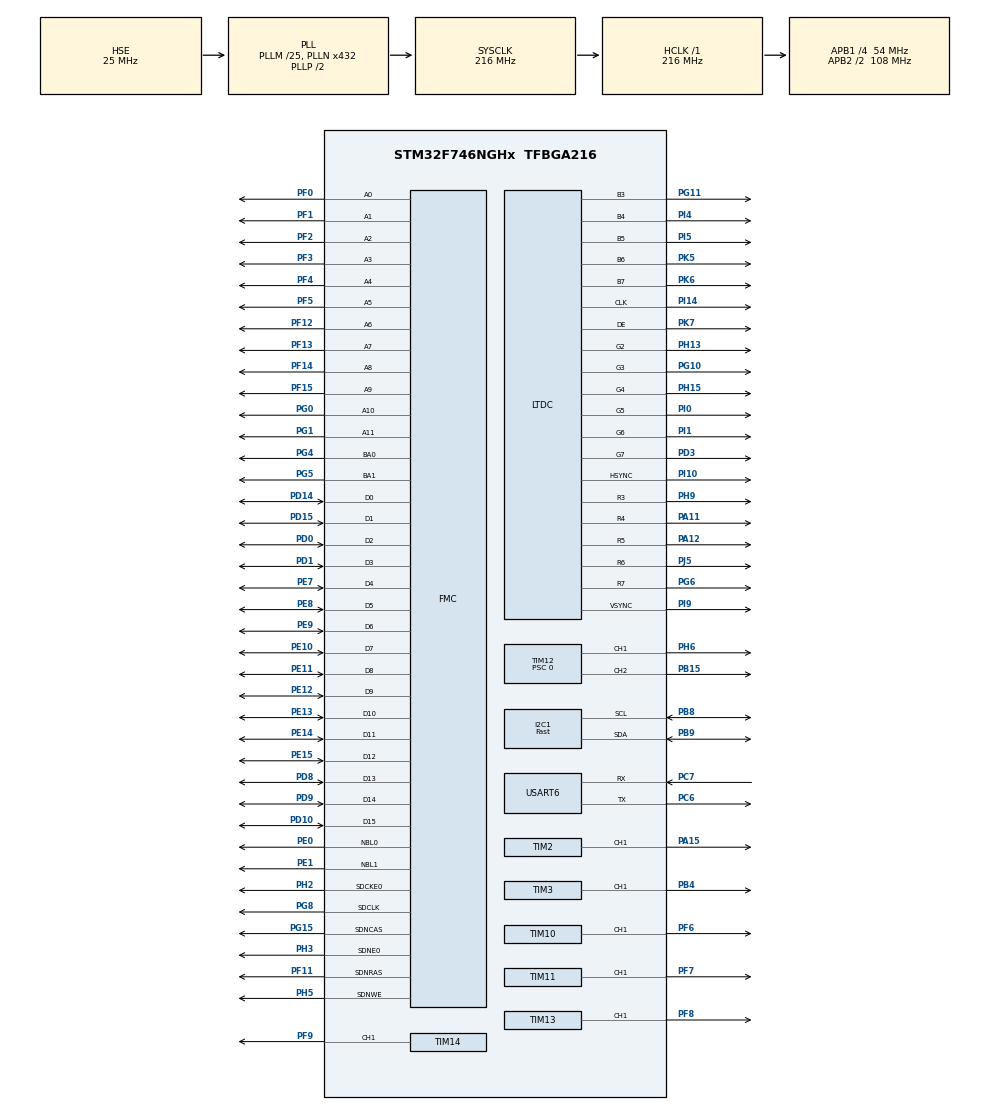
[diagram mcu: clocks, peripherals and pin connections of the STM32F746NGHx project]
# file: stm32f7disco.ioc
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CORTEX_M7.default_mode_Activation=1
DMA2D.ColorMode=DMA2D_OUTPUT_RGB565
FMC.CASLatency1=FMC_SDRAM_CAS_LATENCY_3
FMC.ExitSelfRefreshDelay1=7
FMC.LoadToActiveDelay1=2
FMC.RPDelay1=2
FMC.RPDelay2=2
FMC.ReadBurst1=FMC_SDRAM_RBURST_ENABLE
FMC.ReadBurst2=FMC_SDRAM_RBURST_ENABLE
FMC.RowCycleDelay1=7
FMC.RowCycleDelay2=7
FMC.SDClockPeriod1=FMC_SDRAM_CLOCK_PERIOD_2
FMC.SDClockPeriod2=FMC_SDRAM_CLOCK_PERIOD_2
FMC.SelfRefreshTime1=4
FMC.WriteRecoveryTime1=3
I2C1.I2C_Speed_Mode=I2C_Fast
I2C1.Timing=0x6000030D
LTDC.ActiveH=272
LTDC.ActiveW=480
LTDC.Alpha0_L0=255
LTDC.Alpha0_L1=255
LTDC.Alpha_L1=255
LTDC.FBStartAdress_L0=0xC0000000
LTDC.FBStartAdress_L1=0xC0000000
LTDC.HBP=13
LTDC.HFP=32
LTDC.HSync=41
LTDC.ImageHeight_L0=272
LTDC.ImageHeight_L1=272
LTDC.ImageWidth_L0=963
LTDC.ImageWidth_L1=963
LTDC.Layers=0
LTDC.PixelFormat_L0=LTDC_PIXEL_FORMAT_RGB565
LTDC.VSync=10
LTDC.WindowX0_L1=0
LTDC.WindowX1_L0=480
LTDC.WindowX1_L1=480
LTDC.WindowY1_L0=272
LTDC.WindowY1_L1=272
Mcu.Family=STM32F7
Mcu.Name=STM32F746NGHx
Mcu.Package=TFBGA216
NVIC.PriorityGroup=NVIC_PRIORITYGROUP_4
PA11.Mode=RGB565
PA11.Signal=LTDC_R4
PA12.Mode=RGB565
PA12.Signal=LTDC_R5
PA15.Signal=S_TIM2_CH1_ETR
PB15.Signal=S_TIM12_CH2
PB4.Signal=S_TIM3_CH1
PB8.Mode=I2C
PB8.Signal=I2C1_SCL
PB9.Mode=I2C
PB9.Signal=I2C1_SDA
PC6.Mode=Asynchronous
PC6.Signal=USART6_TX
PC7.Mode=Asynchronous
PC7.Signal=USART6_RX
PD0.Signal=FMC_D2_DA2
PD1.Signal=FMC_D3_DA3
PD10.Signal=FMC_D15_DA15
PD14.Signal=FMC_D0_DA0
PD15.Signal=FMC_D1_DA1
PD3.Mode=RGB565
PD3.Signal=LTDC_G7
PD8.Signal=FMC_D13_DA13
PD9.Signal=FMC_D14_DA14
PE0.Signal=FMC_NBL0
PE1.Signal=FMC_NBL1
PE10.Signal=FMC_D7_DA7
PE11.Signal=FMC_D8_DA8
PE12.Signal=FMC_D9_DA9
PE13.Signal=FMC_D10_DA10
PE14.Signal=FMC_D11_DA11
PE15.Signal=FMC_D12_DA12
PE7.Signal=FMC_D4_DA4
PE8.Signal=FMC_D5_DA5
PE9.Signal=FMC_D6_DA6
PF0.Signal=FMC_A0
PF1.Signal=FMC_A1
PF11.Signal=FMC_SDNRAS
PF12.Signal=FMC_A6
PF13.Signal=FMC_A7
PF14.Signal=FMC_A8
PF15.Signal=FMC_A9
PF2.Signal=FMC_A2
PF3.Signal=FMC_A3
PF4.Signal=FMC_A4
PF5.Signal=FMC_A5
PF6.Signal=S_TIM10_CH1
PF7.Signal=S_TIM11_CH1
PF8.Signal=S_TIM13_CH1
PF9.Signal=S_TIM14_CH1
PG0.Signal=FMC_A10
PG1.Signal=FMC_A11
PG10.Mode=RGB565
PG10.Signal=LTDC_G3
PG11.Mode=RGB565
PG11.Signal=LTDC_B3
PG15.Signal=FMC_SDNCAS
PG4.Signal=FMC_A14_BA0
PG5.Signal=FMC_A15_BA1
PG6.Mode=RGB565
PG6.Signal=LTDC_R7
PG8.Signal=FMC_SDCLK
PH0/OSC_IN.Mode=HSE-External-Clock-Source
PH0/OSC_IN.Signal=RCC_OSC_IN
PH1/OSC_OUT.Mode=HSE-External-Clock-Source
PH1/OSC_OUT.Signal=RCC_OSC_OUT
PH13.Mode=RGB565
PH13.Signal=LTDC_G2
PH15.Mode=RGB565
PH15.Signal=LTDC_G4
PH2.Mode=SdramChipSelect1_1
PH2.Signal=FMC_SDCKE0
PH3.Mode=SdramChipSelect1_1
PH3.Signal=FMC_SDNE0
PH5.Signal=FMC_SDNWE
PH6.Signal=S_TIM12_CH1
PH9.Mode=RGB565
PH9.Signal=LTDC_R3
PI0.Mode=RGB565
PI0.Signal=LTDC_G5
PI1.Mode=RGB565
PI1.Signal=LTDC_G6
PI10.Mode=RGB565
PI10.Signal=LTDC_HSYNC
PI14.Mode=RGB565
PI14.Signal=LTDC_CLK
PI4.Mode=RGB565
PI4.Signal=LTDC_B4
PI5.Mode=RGB565
PI5.Signal=LTDC_B5
PI9.Mode=RGB565
PI9.Signal=LTDC_VSYNC
PJ5.Mode=RGB565
PJ5.Signal=LTDC_R6
PK5.Mode=RGB565
PK5.Signal=LTDC_B6
PK6.Mode=RGB565
PK6.Signal=LTDC_B7
PK7.Mode=RGB565
PK7.Signal=LTDC_DE
ProjectManager.HeapSize=0x200
ProjectManager.StackSize=0x400
ProjectManager.TargetToolchain=STM32CubeIDE
RCC.AHBFreq_Value=216000000
RCC.APB1CLKDivider=RCC_HCLK_DIV4
RCC.APB1Freq_Value=54000000
RCC.APB1TimFreq_Value=108000000
RCC.APB2CLKDivider=RCC_HCLK_DIV2
RCC.APB2Freq_Value=108000000
RCC.APB2TimFreq_Value=216000000
RCC.CortexFreq_Value=216000000
RCC.HCLKFreq_Value=216000000
RCC.HSE_VALUE=25000000
RCC.HSI_VALUE=16000000
RCC.LSE_VALUE=32768
RCC.PLLM=25
RCC.PLLN=432
RCC.PLLSAIR=4
RCC.PLLSourceVirtual=RCC_PLLSOURCE_HSE
RCC.PWR_Regulator_Voltage_Scale=PWR_REGULATOR_VOLTAGE_SCALE1
RCC.SYSCLKFreq_VALUE=216000000
RCC.SYSCLKSource=RCC_SYSCLKSOURCE_PLLCLK
RCC.USBFreq_Value=216000000
RCC.VCOOutputFreq_Value=432000000
SH.FMC_A0.0=FMC_A0,12b-sda1
SH.FMC_A1.0=FMC_A1,12b-sda1
SH.FMC_A10.0=FMC_A10,12b-sda1
SH.FMC_A11.0=FMC_A11,12b-sda1
SH.FMC_A14_BA0.0=FMC_BA0,FourSdramBanks1
SH.FMC_A15_BA1.0=FMC_BA1,FourSdramBanks1
SH.FMC_A2.0=FMC_A2,12b-sda1
SH.FMC_A3.0=FMC_A3,12b-sda1
SH.FMC_A4.0=FMC_A4,12b-sda1
SH.FMC_A5.0=FMC_A5,12b-sda1
SH.FMC_A6.0=FMC_A6,12b-sda1
SH.FMC_A7.0=FMC_A7,12b-sda1
SH.FMC_A8.0=FMC_A8,12b-sda1
SH.FMC_A9.0=FMC_A9,12b-sda1
SH.FMC_D0_DA0.0=FMC_D0,sd-16b-d1
SH.FMC_D10_DA10.0=FMC_D10,sd-16b-d1
SH.FMC_D11_DA11.0=FMC_D11,sd-16b-d1
SH.FMC_D12_DA12.0=FMC_D12,sd-16b-d1
SH.FMC_D13_DA13.0=FMC_D13,sd-16b-d1
SH.FMC_D14_DA14.0=FMC_D14,sd-16b-d1
SH.FMC_D15_DA15.0=FMC_D15,sd-16b-d1
SH.FMC_D1_DA1.0=FMC_D1,sd-16b-d1
SH.FMC_D2_DA2.0=FMC_D2,sd-16b-d1
SH.FMC_D3_DA3.0=FMC_D3,sd-16b-d1
SH.FMC_D4_DA4.0=FMC_D4,sd-16b-d1
SH.FMC_D5_DA5.0=FMC_D5,sd-16b-d1
SH.FMC_D6_DA6.0=FMC_D6,sd-16b-d1
SH.FMC_D7_DA7.0=FMC_D7,sd-16b-d1
SH.FMC_D8_DA8.0=FMC_D8,sd-16b-d1
SH.FMC_D9_DA9.0=FMC_D9,sd-16b-d1
SH.FMC_NBL0.0=FMC_NBL0,Sd2ByteEnable1
SH.FMC_NBL1.0=FMC_NBL1,Sd2ByteEnable1
SH.FMC_SDCLK.0=FMC_SDCLK,12b-sda1
SH.FMC_SDNCAS.0=FMC_SDNCAS,12b-sda1
SH.FMC_SDNRAS.0=FMC_SDNRAS,12b-sda1
SH.FMC_SDNWE.0=FMC_SDNWE,12b-sda1
SH.S_TIM10_CH1.0=TIM10_CH1,PWM Generation1 CH1
SH.S_TIM11_CH1.0=TIM11_CH1,PWM Generation1 CH1
SH.S_TIM12_CH1.0=TIM12_CH1,PWM Generation1 CH1
SH.S_TIM12_CH2.0=TIM12_CH2,PWM Generation2 CH2
SH.S_TIM13_CH1.0=TIM13_CH1,PWM Generation1 CH1
SH.S_TIM14_CH1.0=TIM14_CH1,PWM Generation1 CH1
SH.S_TIM2_CH1_ETR.0=TIM2_CH1,PWM Generation1 CH1
SH.S_TIM3_CH1.0=TIM3_CH1,PWM Generation1 CH1
TIM1.AutoReloadPreload=TIM_AUTORELOAD_PRELOAD_ENABLE
TIM1.Period=10799
TIM1.Prescaler=215
TIM10.AutoReloadPreload=TIM_AUTORELOAD_PRELOAD_ENABLE
TIM10.Channel=TIM_CHANNEL_1
TIM10.Period=1000-1
TIM10.Prescaler=0
TIM11.AutoReloadPreload=TIM_AUTORELOAD_PRELOAD_ENABLE
TIM11.Channel=TIM_CHANNEL_1
TIM11.Period=1000-1
TIM11.Prescaler=0
TIM12.AutoReloadPreload=TIM_AUTORELOAD_PRELOAD_ENABLE
TIM12.Channel-PWM\ Generation1\ CH1=TIM_CHANNEL_1
TIM12.Channel-PWM\ Generation2\ CH2=TIM_CHANNEL_2
TIM12.Period=999
TIM12.Prescaler=0
TIM13.AutoReloadPreload=TIM_AUTORELOAD_PRELOAD_ENABLE
TIM13.Channel=TIM_CHANNEL_1
TIM13.Period=1000-1
TIM13.Prescaler=0
TIM14.AutoReloadPreload=TIM_AUTORELOAD_PRELOAD_ENABLE
TIM14.Channel=TIM_CHANNEL_1
TIM14.Period=1000-1
TIM14.Prescaler=0
TIM2.AutoReloadPreload=TIM_AUTORELOAD_PRELOAD_ENABLE
TIM2.Channel-PWM\ Generation1\ CH1=TIM_CHANNEL_1
TIM2.Period=10799
TIM3.Channel-PWM\ Generation1\ CH1=TIM_CHANNEL_1
TIM3.Period=1000-1
TIM3.Prescaler=0
USART6.VirtualMode-Asynchronous=VM_ASYNC
VP_DMA2D_VS_DMA2D.Mode=DMA2D_Activate
VP_TIM10_VS_ClockSourceINT.Mode=Enable_Timer
VP_TIM11_VS_ClockSourceINT.Mode=Enable_Timer
VP_TIM12_VS_ClockSourceINT.Mode=Internal
VP_TIM13_VS_ClockSourceINT.Mode=Enable_Timer
VP_TIM14_VS_ClockSourceINT.Mode=Enable_Timer
VP_TIM1_VS_ClockSourceINT.Mode=Internal
VP_TIM3_VS_ClockSourceINT.Mode=Internal
board=custom

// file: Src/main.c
/* USER CODE BEGIN Header */
/**
  ******************************************************************************
  * @file           : main.c
  * @brief          : Main program body
  ******************************************************************************
  * @attention
  *
  * Copyright (c) 2026 STMicroelectronics.
  * All rights reserved.
  *
  * This software is licensed under terms that can be found in the LICENSE file
  * in the root directory of this software component.
  * If no LICENSE file comes with this software, it is provided AS-IS.
  *
  ******************************************************************************
  */
/* USER CODE END Header */
#include "main.h"
#include "dma2d.h"
#include "i2c.h"
#include "ltdc.h"
#include "tim.h"
#include "usart.h"
#include "gpio.h"
#include "fmc.h"

/* USER CODE BEGIN Includes */
#include "app.h"
#include "imu_min_test.h"
#include "stm32746g_discovery_lcd.h"
#ifdef BSP_LCD_TEST_MODE
#include "lcd_bsp_test.h"
#endif
#ifdef LCD_TEST_MODE
#include "lcd_test.h"
#endif

/* USER CODE END Includes */

void SystemClock_Config(void);
static void MPU_Config(void);

/* USER CODE BEGIN 0 */
extern volatile uint32_t g_debug_stage;

/* USER CODE END 0 */

int main(void)
{

  /* MPU Configuration--------------------------------------------------------*/
  g_debug_stage = 1u;
  MPU_Config();

  /* MCU Configuration--------------------------------------------------------*/

  /* Reset of all peripherals, Initializes the Flash interface and the Systick. */
  g_debug_stage = 2u;
  HAL_Init();

  /* Configure the system clock */
  g_debug_stage = 3u;
  SystemClock_Config();

#ifdef BSP_LCD_TEST_MODE
  LCD_BSP_Test_Run();
#else
  /* Initialize all configured peripherals */
  g_debug_stage = 4u;
  MX_GPIO_Init();
  g_debug_stage = 5u;
  MX_I2C1_Init();
#ifdef IMU_MIN_TEST_MODE
  g_debug_stage = 14u;
  MX_DMA2D_Init();
  g_debug_stage = 15u;
  BSP_LCD_Init();
  g_debug_stage = 16u;
  BSP_LCD_LayerDefaultInit(0, LCD_FB_START_ADDRESS);
  g_debug_stage = 17u;
  BSP_LCD_SelectLayer(0);
  g_debug_stage = 18u;
  BSP_LCD_DisplayOn();
  g_debug_stage = 90u;
  IMU_Min_Test_Run();
#else
  g_debug_stage = 6u;
  MX_TIM1_Init();
  g_debug_stage = 7u;
  MX_TIM3_Init();
  g_debug_stage = 8u;
  MX_TIM10_Init();
  g_debug_stage = 9u;
  MX_TIM11_Init();
  g_debug_stage = 10u;
  MX_TIM12_Init();
  g_debug_stage = 11u;
  MX_TIM13_Init();
  g_debug_stage = 12u;
  MX_TIM14_Init();
  g_debug_stage = 13u;
  MX_USART6_UART_Init();
  g_debug_stage = 14u;
  MX_DMA2D_Init();
  g_debug_stage = 15u;
  BSP_LCD_Init();
  g_debug_stage = 16u;
  BSP_LCD_LayerDefaultInit(0, LCD_FB_START_ADDRESS);
  g_debug_stage = 17u;
  BSP_LCD_SelectLayer(0);
  g_debug_stage = 18u;
  BSP_LCD_DisplayOn();
  g_debug_stage = 19u;
  MX_TIM2_Init();
  g_debug_stage = 20u;
  /* USER CODE BEGIN 2 */
#ifdef LCD_TEST_MODE
  LCD_Test_Run();
#else
#ifdef MOTOR_ESP32_DIAG_MODE
  App_MotorEsp32Diag_Run();
#else
  App_Run();
#endif
#endif

  /* USER CODE END 2 */
#endif
#endif

  /* Infinite loop */
  while (1)
  {

  }
}

void SystemClock_Config(void)
{
  RCC_OscInitTypeDef RCC_OscInitStruct = {0};
  RCC_ClkInitTypeDef RCC_ClkInitStruct = {0};

  /** Configure the main internal regulator output voltage
  */
  __HAL_RCC_PWR_CLK_ENABLE();
  __HAL_PWR_VOLTAGESCALING_CONFIG(PWR_REGULATOR_VOLTAGE_SCALE1);

  /** Initializes the RCC Oscillators according to the specified parameters
  * in the RCC_OscInitTypeDef structure.
  */
  RCC_OscInitStruct.OscillatorType = RCC_OSCILLATORTYPE_HSE;
  RCC_OscInitStruct.HSEState = RCC_HSE_BYPASS;
  RCC_OscInitStruct.PLL.PLLState = RCC_PLL_ON;
  RCC_OscInitStruct.PLL.PLLSource = RCC_PLLSOURCE_HSE;
  RCC_OscInitStruct.PLL.PLLM = 25;
  RCC_OscInitStruct.PLL.PLLN = 432;
  RCC_OscInitStruct.PLL.PLLP = RCC_PLLP_DIV2;
  RCC_OscInitStruct.PLL.PLLQ = 2;
  if (HAL_RCC_OscConfig(&RCC_OscInitStruct) != HAL_OK)
  {
    Error_Handler();
  }

  /** Activate the Over-Drive mode
  */
  if (HAL_PWREx_EnableOverDrive() != HAL_OK)
  {
    Error_Handler();
  }

  /** Initializes the CPU, AHB and APB buses clocks
  */
  RCC_ClkInitStruct.ClockType = RCC_CLOCKTYPE_HCLK|RCC_CLOCKTYPE_SYSCLK
                              |RCC_CLOCKTYPE_PCLK1|RCC_CLOCKTYPE_PCLK2;
  RCC_ClkInitStruct.SYSCLKSource = RCC_SYSCLKSOURCE_PLLCLK;
  RCC_ClkInitStruct.AHBCLKDivider = RCC_SYSCLK_DIV1;
  RCC_ClkInitStruct.APB1CLKDivider = RCC_HCLK_DIV4;
  RCC_ClkInitStruct.APB2CLKDivider = RCC_HCLK_DIV2;

  if (HAL_RCC_ClockConfig(&RCC_ClkInitStruct, FLASH_LATENCY_7) != HAL_OK)
  {
    Error_Handler();
  }
}

 /* MPU Configuration */

void MPU_Config(void)
{
  MPU_Region_InitTypeDef MPU_InitStruct = {0};

  /* Disables the MPU */
  HAL_MPU_Disable();

  /** Initializes and configures the Region and the memory to be protected
  */
  MPU_InitStruct.Enable = MPU_REGION_ENABLE;
  MPU_InitStruct.Number = MPU_REGION_NUMBER0;
  MPU_InitStruct.BaseAddress = 0x0;
  MPU_InitStruct.Size = MPU_REGION_SIZE_4GB;
  MPU_InitStruct.SubRegionDisable = 0x87;
  MPU_InitStruct.TypeExtField = MPU_TEX_LEVEL0;
  MPU_InitStruct.AccessPermission = MPU_REGION_NO_ACCESS;
  MPU_InitStruct.DisableExec = MPU_INSTRUCTION_ACCESS_DISABLE;
  MPU_InitStruct.IsShareable = MPU_ACCESS_SHAREABLE;
  MPU_InitStruct.IsCacheable = MPU_ACCESS_NOT_CACHEABLE;
  MPU_InitStruct.IsBufferable = MPU_ACCESS_NOT_BUFFERABLE;

  HAL_MPU_ConfigRegion(&MPU_InitStruct);

  /** Allows access to FMC control registers needed to initialize SDRAM.
  */
  MPU_InitStruct.Enable = MPU_REGION_ENABLE;
  MPU_InitStruct.Number = MPU_REGION_NUMBER1;
  MPU_InitStruct.BaseAddress = 0xA0000000;
  MPU_InitStruct.Size = MPU_REGION_SIZE_8KB;
  MPU_InitStruct.SubRegionDisable = 0x0;
  MPU_InitStruct.TypeExtField = MPU_TEX_LEVEL0;
  MPU_InitStruct.AccessPermission = MPU_REGION_FULL_ACCESS;
  MPU_InitStruct.DisableExec = MPU_INSTRUCTION_ACCESS_DISABLE;
  MPU_InitStruct.IsShareable = MPU_ACCESS_SHAREABLE;
  MPU_InitStruct.IsCacheable = MPU_ACCESS_NOT_CACHEABLE;
  MPU_InitStruct.IsBufferable = MPU_ACCESS_NOT_BUFFERABLE;

  HAL_MPU_ConfigRegion(&MPU_InitStruct);

  /** Allows access to external SDRAM used as the LTDC framebuffer.
  */
  MPU_InitStruct.Enable = MPU_REGION_ENABLE;
  MPU_InitStruct.Number = MPU_REGION_NUMBER2;
  MPU_InitStruct.BaseAddress = 0xC0000000;
  MPU_InitStruct.Size = MPU_REGION_SIZE_8MB;
  MPU_InitStruct.SubRegionDisable = 0x0;
  MPU_InitStruct.TypeExtField = MPU_TEX_LEVEL0;
  MPU_InitStruct.AccessPermission = MPU_REGION_FULL_ACCESS;
  MPU_InitStruct.DisableExec = MPU_INSTRUCTION_ACCESS_ENABLE;
  MPU_InitStruct.IsShareable = MPU_ACCESS_NOT_SHAREABLE;
  MPU_InitStruct.IsCacheable = MPU_ACCESS_NOT_CACHEABLE;
  MPU_InitStruct.IsBufferable = MPU_ACCESS_NOT_BUFFERABLE;

  HAL_MPU_ConfigRegion(&MPU_InitStruct);
  /* Enables the MPU */
  HAL_MPU_Enable(MPU_PRIVILEGED_DEFAULT);

}

void Error_Handler(void)
{
  __disable_irq();
  while (1)
  {
  }
}
